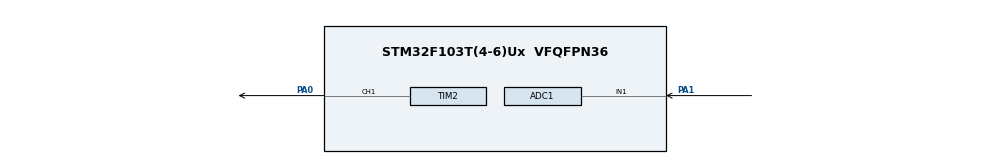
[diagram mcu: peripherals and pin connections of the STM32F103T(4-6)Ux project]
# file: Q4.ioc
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ADC1.Channel-0\#ChannelRegularConversion=ADC_CHANNEL_1
ADC1.NbrOfConversionFlag=1
ADC1.Rank-0\#ChannelRegularConversion=1
ADC1.SamplingTime-0\#ChannelRegularConversion=ADC_SAMPLETIME_1CYCLE_5
ADC1.master=1
Mcu.Family=STM32F1
Mcu.Name=STM32F103T(4-6)Ux
Mcu.Package=VFQFPN36
NVIC.PriorityGroup=NVIC_PRIORITYGROUP_4
PA0-WKUP.Signal=S_TIM2_CH1_ETR
PA1.Signal=ADCx_IN1
ProjectManager.HeapSize=0x200
ProjectManager.StackSize=0x400
ProjectManager.TargetToolchain=STM32CubeIDE
RCC.APB1Freq_Value=8000000
RCC.APB2Freq_Value=8000000
SH.ADCx_IN1.0=ADC1_IN1,IN1
SH.S_TIM2_CH1_ETR.0=TIM2_CH1,PWM Generation1 CH1
TIM2.Channel-PWM\ Generation1\ CH1=TIM_CHANNEL_1
TIM2.Period=999
TIM2.Prescaler=99
VP_SYS_VS_ND.Mode=No_Debug
board=custom

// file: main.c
/* USER CODE BEGIN Header */
/**
  ******************************************************************************
  * @file           : main.c
  * @brief          : Main program body
  ******************************************************************************
  * @attention
  *
  * Copyright (c) 2025 STMicroelectronics.
  * All rights reserved.
  *
  * This software is licensed under terms that can be found in the LICENSE file
  * in the root directory of this software component.
  * If no LICENSE file comes with this software, it is provided AS-IS.
  *
  ******************************************************************************
  */
/* USER CODE END Header */
#include "main.h"
#include "adc.h"
#include "tim.h"
#include "gpio.h"

void SystemClock_Config(void);

int main(void)
{

  /* MCU Configuration--------------------------------------------------------*/

  /* Reset of all peripherals, Initializes the Flash interface and the Systick. */
  HAL_Init();

  /* Configure the system clock */
  SystemClock_Config();

  /* Initialize all configured peripherals */
  MX_GPIO_Init();
  MX_TIM2_Init();
  MX_ADC1_Init();
  /* USER CODE BEGIN 2 */
  HAL_TIM_PWM_Start(&htim2, TIM_CHANNEL_1);
  	  uint16_t adc_val;
  	  float duty_percent;
  	  uint32_t ccr_val;
   /* USER CODE END 2 */

  /* Infinite loop */
  /* USER CODE BEGIN WHILE */
  while (1)
  {
	  TIM2->CCR1 = 400;
    /* USER CODE END WHILE */
	  HAL_ADC_Start(&hadc1);
	  	      HAL_ADC_PollForConversion(&hadc1, HAL_MAX_DELAY);
	  	      adc_val = HAL_ADC_GetValue(&hadc1);

	  	      duty_percent = ((adc_val / 4095.0f) * 80.0f) + 10.0f;

	  	      ccr_val = (duty_percent / 100.0f) * (__HAL_TIM_GET_AUTORELOAD(&htim2) + 1);

	  	      __HAL_TIM_SET_COMPARE(&htim2, TIM_CHANNEL_1, ccr_val);

	  	      HAL_Delay(50);
  }
}

void SystemClock_Config(void)
{
  RCC_OscInitTypeDef RCC_OscInitStruct = {0};
  RCC_ClkInitTypeDef RCC_ClkInitStruct = {0};
  RCC_PeriphCLKInitTypeDef PeriphClkInit = {0};

  /** Initializes the RCC Oscillators according to the specified parameters
  * in the RCC_OscInitTypeDef structure.
  */
  RCC_OscInitStruct.OscillatorType = RCC_OSCILLATORTYPE_HSI;
  RCC_OscInitStruct.HSIState = RCC_HSI_ON;
  RCC_OscInitStruct.HSICalibrationValue = RCC_HSICALIBRATION_DEFAULT;
  RCC_OscInitStruct.PLL.PLLState = RCC_PLL_NONE;
  if (HAL_RCC_OscConfig(&RCC_OscInitStruct) != HAL_OK)
  {
    Error_Handler();
  }

  /** Initializes the CPU, AHB and APB buses clocks
  */
  RCC_ClkInitStruct.ClockType = RCC_CLOCKTYPE_HCLK|RCC_CLOCKTYPE_SYSCLK
                              |RCC_CLOCKTYPE_PCLK1|RCC_CLOCKTYPE_PCLK2;
  RCC_ClkInitStruct.SYSCLKSource = RCC_SYSCLKSOURCE_HSI;
  RCC_ClkInitStruct.AHBCLKDivider = RCC_SYSCLK_DIV1;
  RCC_ClkInitStruct.APB1CLKDivider = RCC_HCLK_DIV1;
  RCC_ClkInitStruct.APB2CLKDivider = RCC_HCLK_DIV1;

  if (HAL_RCC_ClockConfig(&RCC_ClkInitStruct, FLASH_LATENCY_0) != HAL_OK)
  {
    Error_Handler();
  }
  PeriphClkInit.PeriphClockSelection = RCC_PERIPHCLK_ADC;
  PeriphClkInit.AdcClockSelection = RCC_ADCPCLK2_DIV2;
  if (HAL_RCCEx_PeriphCLKConfig(&PeriphClkInit) != HAL_OK)
  {
    Error_Handler();
  }
}

void Error_Handler(void)
{
  __disable_irq();
  while (1)
  {
  }
}
